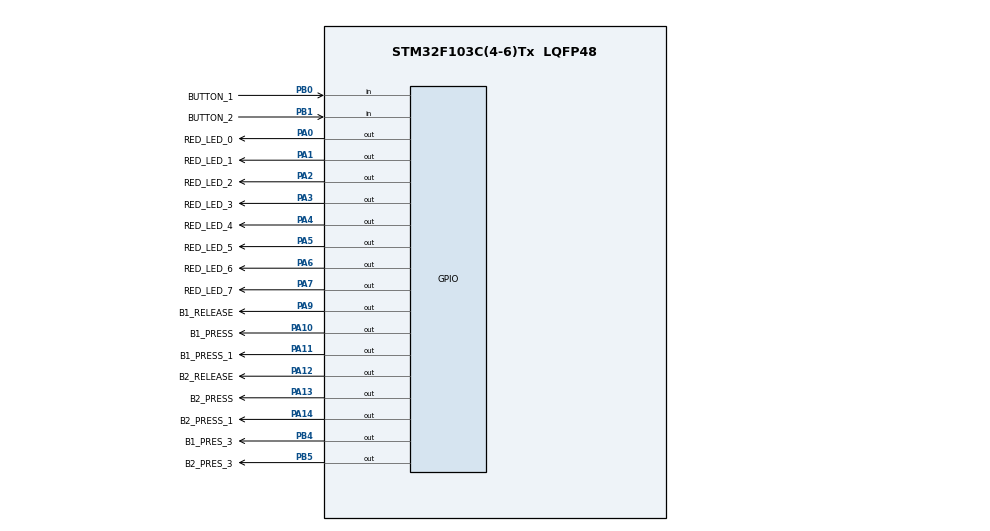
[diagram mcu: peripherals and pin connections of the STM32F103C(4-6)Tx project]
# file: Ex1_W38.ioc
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Mcu.Family=STM32F1
PD1-OSC_OUT.Mode=HSE-External-Oscillator
PA9.GPIO_Label=B1_RELEASE
PA14.GPIO_Label=B2_PRESS_1
PA11.GPIO_Label=B1_PRESS_1
PA6.GPIO_Label=RED_LED_6
PB0.GPIO_Label=BUTTON_1
PD0-OSC_IN.Signal=RCC_OSC_IN
VP_SYS_VS_ND.Mode=No_Debug
PA12.GPIO_Label=B2_RELEASE
ProjectManager.StackSize=0x400
PA0-WKUP.GPIO_Label=RED_LED_0
PA0-WKUP.Signal=GPIO_Output
PD1-OSC_OUT.Signal=RCC_OSC_OUT
PA13.Signal=GPIO_Output
PA12.Signal=GPIO_Output
ProjectManager.TargetToolchain=STM32CubeIDE
PA9.Signal=GPIO_Output
PA1.Signal=GPIO_Output
PD0-OSC_IN.Mode=HSE-External-Oscillator
PA5.Signal=GPIO_Output
board=custom
RCC.APB2Freq_Value=8000000
PB4.GPIO_Label=B1_PRES_3
VP_TIM2_VS_ClockSourceINT.Mode=Internal
PB1.GPIO_Label=BUTTON_2
NVIC.TIM2_IRQn=true\:0\:0\:false\:false\:true\:true\:true
PA1.GPIO_Label=RED_LED_1
PA10.GPIO_Label=B1_PRESS
TIM2.Period=9
Mcu.Name=STM32F103C(4-6)Tx
PA2.Signal=GPIO_Output
PA13.GPIO_Label=B2_PRESS
PA4.Signal=GPIO_Output
Mcu.Package=LQFP48
PB5.Signal=GPIO_Output
TIM2.Prescaler=7999
PA6.Signal=GPIO_Output
PB1.Signal=GPIO_Input
PA7.GPIO_Label=RED_LED_7
PA5.GPIO_Label=RED_LED_5
PA2.GPIO_Label=RED_LED_2
PA11.Signal=GPIO_Output
PA10.Signal=GPIO_Output
PA14.Signal=GPIO_Output
ProjectManager.HeapSize=0x200
NVIC.PriorityGroup=NVIC_PRIORITYGROUP_4
PB5.GPIO_Label=B2_PRES_3
RCC.APB1Freq_Value=8000000
PB0.Signal=GPIO_Input
PA4.GPIO_Label=RED_LED_4
PB4.Signal=GPIO_Output
PA3.GPIO_Label=RED_LED_3
PA3.Signal=GPIO_Output
PA7.Signal=GPIO_Output

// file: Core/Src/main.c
/* USER CODE BEGIN Header */
/**
  ******************************************************************************
  * @file           : main.c
  * @brief          : Main program body
  ******************************************************************************
  * @attention
  *
  * <h2><center>&copy; Copyright (c) 2021 STMicroelectronics.
  * All rights reserved.</center></h2>
  *
  * This software component is licensed by ST under BSD 3-Clause license,
  * the "License"; You may not use this file except in compliance with the
  * License. You may obtain a copy of the License at:
  *                        opensource.org/licenses/BSD-3-Clause
  *
  ******************************************************************************
  */
/* USER CODE END Header */
#include "main.h"
#include "input_processing.h"

#define time_auto_incre_I 50 // 0.5 s
#define time_auto_incre_II 10 //0.1 s

int count = 20;
int down=100; //1down = 10ms

int flag_auto_incre_I = 0;
int flag_auto_incre_II = 0;
int flag_auto_decre_I = 0;
int flag_auto_decre_II = 0;

enum ButtonState {BUTTONS_RELEASED, BUTTON1_PRESSED, BUTTON1_PRESSED_MORE_THAN_1_SECOND, BUTTON1_PRESSED_MORE_THAN_3_SECOND,
									BUTTON2_PRESSED, BUTTON2_PRESSED_MORE_THAN_1_SECOND, BUTTON2_PRESSED_MORE_THAN_3_SECOND};
enum ButtonState buttonState = BUTTONS_RELEASED ;
void ledofbutton(void)
{
	switch ( buttonState ){
		case BUTTONS_RELEASED:
			HAL_GPIO_WritePin(GPIOA, GPIO_PIN_9, 0);
			HAL_GPIO_WritePin(GPIOA, GPIO_PIN_10, 1);
			HAL_GPIO_WritePin(GPIOA, GPIO_PIN_11, 1);
			HAL_GPIO_WritePin(GPIOB, GPIO_PIN_4, 1);
			HAL_GPIO_WritePin(GPIOA, GPIO_PIN_12, 0);
			HAL_GPIO_WritePin(GPIOA, GPIO_PIN_13, 1);
			HAL_GPIO_WritePin(GPIOA, GPIO_PIN_14, 1);
			HAL_GPIO_WritePin(GPIOB, GPIO_PIN_5, 1);
			break;
		case BUTTON1_PRESSED:
			HAL_GPIO_WritePin(GPIOA, GPIO_PIN_9, 1);
			HAL_GPIO_WritePin(GPIOA, GPIO_PIN_10, 0);
			HAL_GPIO_WritePin(GPIOA, GPIO_PIN_11, 1);
			HAL_GPIO_WritePin(GPIOB, GPIO_PIN_4, 1);
			break;
		case BUTTON1_PRESSED_MORE_THAN_1_SECOND:
			HAL_GPIO_WritePin(GPIOA, GPIO_PIN_9, 1);
			HAL_GPIO_WritePin(GPIOA, GPIO_PIN_10, 1);
			HAL_GPIO_WritePin(GPIOA, GPIO_PIN_11, 0);
			HAL_GPIO_WritePin(GPIOB, GPIO_PIN_4, 1);
			break;
		case BUTTON1_PRESSED_MORE_THAN_3_SECOND:
			HAL_GPIO_WritePin(GPIOA, GPIO_PIN_9, 1);
			HAL_GPIO_WritePin(GPIOA, GPIO_PIN_10, 1);
			HAL_GPIO_WritePin(GPIOA, GPIO_PIN_11, 1);
			HAL_GPIO_WritePin(GPIOB, GPIO_PIN_4, 0);
			break;
		case BUTTON2_PRESSED:
			HAL_GPIO_WritePin(GPIOA, GPIO_PIN_12, 1);
			HAL_GPIO_WritePin(GPIOA, GPIO_PIN_13, 0);
			HAL_GPIO_WritePin(GPIOA, GPIO_PIN_14, 1);
			HAL_GPIO_WritePin(GPIOB, GPIO_PIN_5, 1);
			break;
		case BUTTON2_PRESSED_MORE_THAN_1_SECOND:
			HAL_GPIO_WritePin(GPIOA, GPIO_PIN_12, 1);
			HAL_GPIO_WritePin(GPIOA, GPIO_PIN_13, 1);
			HAL_GPIO_WritePin(GPIOA, GPIO_PIN_14, 0);
			HAL_GPIO_WritePin(GPIOB, GPIO_PIN_5, 1);
			break;
		case BUTTON2_PRESSED_MORE_THAN_3_SECOND:
			HAL_GPIO_WritePin(GPIOA, GPIO_PIN_12, 1);
			HAL_GPIO_WritePin(GPIOA, GPIO_PIN_13, 1);
			HAL_GPIO_WritePin(GPIOA, GPIO_PIN_14, 1);
			HAL_GPIO_WritePin(GPIOB, GPIO_PIN_5, 0);
			break;
		default:
			break;
	}
}
void fsm_for_input_processing(void){
	ledofbutton();
	switch ( buttonState ){
	case BUTTONS_RELEASED:
		if(get_button_value(0) == GPIO_PIN_RESET ) {
			buttonState = BUTTON1_PRESSED;
			count++;
		}
		else
		{
			if(get_button_value(1) == GPIO_PIN_RESET ) {
				buttonState = BUTTON2_PRESSED;
				count--;
			}
		}
		break;
	case BUTTON1_PRESSED:
		if(get_button_value(0) == GPIO_PIN_SET && get_button_value(1) == GPIO_PIN_SET ) { // release 2 button
			buttonState = BUTTONS_RELEASED ;
		} else {
			if(get_button_value(0) == GPIO_PIN_SET && get_button_value(1) == GPIO_PIN_RESET ) { // release button 0 but still press button 1
				buttonState = BUTTON2_PRESSED ;
			}
			else
			{
				if( get_flag_for_button_press_1s (0) == 1) {
					buttonState = BUTTON1_PRESSED_MORE_THAN_1_SECOND ;
				}
			}
		}
		break;
	case BUTTON1_PRESSED_MORE_THAN_1_SECOND :
		if(get_button_value(0) == GPIO_PIN_SET && get_button_value(1) == GPIO_PIN_SET) { // release 2 button
			buttonState = BUTTONS_RELEASED ;
			flag_auto_incre_I = 0;
		}
		else
		{
			if(get_button_value(0) == GPIO_PIN_SET && get_button_value(1) == GPIO_PIN_RESET ) { // release button 0 but still press button 1
				buttonState = BUTTON2_PRESSED ;
				count--;
				flag_auto_incre_I = 0;
			}
			else
			{
				flag_auto_incre_I = 1;
				if( get_flag_for_button_press_3s (0) == 1) {
					buttonState = BUTTON1_PRESSED_MORE_THAN_3_SECOND ;
					flag_auto_incre_I = 0;
				}
			}
		}
		break;
	case BUTTON1_PRESSED_MORE_THAN_3_SECOND :
		if(get_button_value(0) == GPIO_PIN_SET && get_button_value(1) == GPIO_PIN_SET ) { // release 2 button
			buttonState = BUTTONS_RELEASED ;
			flag_auto_incre_II = 0;
		}
		else
		{
			if(get_button_value(0) == GPIO_PIN_SET && get_button_value(1) == GPIO_PIN_RESET ) { // release button 0 but still press button 1
				buttonState = BUTTON2_PRESSED ;
				count--;
				flag_auto_incre_II = 0;
			}
			else
			{
				flag_auto_incre_II = 1;
			}
		}
		break;
	case BUTTON2_PRESSED:
		if(get_button_value(0) == GPIO_PIN_SET && get_button_value(1) == GPIO_PIN_SET ) { // release 2 button
			buttonState = BUTTONS_RELEASED ;
		} else {
			if(get_button_value(0) == GPIO_PIN_RESET && get_button_value(1) == GPIO_PIN_RESET ) { // press button 1 while pressing button 2
				buttonState = BUTTON1_PRESSED ;
				count++;
			}
			else
			{
				if( get_flag_for_button_press_1s (1) == 1) {
					buttonState = BUTTON2_PRESSED_MORE_THAN_1_SECOND ;
				}
			}
		}
		break;
	case BUTTON2_PRESSED_MORE_THAN_1_SECOND:
		if(get_button_value(0) == GPIO_PIN_SET && get_button_value(1) == GPIO_PIN_SET) { // release 2 button
			buttonState = BUTTONS_RELEASED ;
			flag_auto_decre_I = 0;
		}
		else
		{
			if(get_button_value(0) == GPIO_PIN_RESET && get_button_value(1) == GPIO_PIN_RESET ) { // press button 1 while pressing button 2
				buttonState = BUTTON1_PRESSED ;
				flag_auto_decre_I = 0;
				count++;
			}
			else
			{
				flag_auto_decre_I = 1;
				if( get_flag_for_button_press_3s (1) == 1) {
					buttonState = BUTTON2_PRESSED_MORE_THAN_3_SECOND ;
					flag_auto_decre_I = 0;
				}
			}
		}
		break;
	case BUTTON2_PRESSED_MORE_THAN_3_SECOND:
		if(get_button_value(0) == GPIO_PIN_SET && get_button_value(1) == GPIO_PIN_SET ) { // release 2 button
			buttonState = BUTTONS_RELEASED ;
			flag_auto_decre_II = 0;
		}
		else
		{
			if(get_button_value(0) == GPIO_PIN_RESET && get_button_value(1) == GPIO_PIN_RESET ) { // release button 0 but still press button 1
				buttonState = BUTTON1_PRESSED ;
				count++;
				flag_auto_decre_II = 0;
			}
			else
			{
				flag_auto_decre_II = 1;
			}
		}
		break;
	default:
			break;
	}
}

void display8leds(int value)
{
	if(value>=0)
	{
		int bin[8];
		for(int i=0; i<8;i++)
		{
			bin[i]=1-value%2;
			value/=2;
		}
		HAL_GPIO_WritePin(GPIOA, GPIO_PIN_0, bin[0]);
		HAL_GPIO_WritePin(GPIOA, GPIO_PIN_1, bin[1]);
		HAL_GPIO_WritePin(GPIOA, GPIO_PIN_2, bin[2]);
		HAL_GPIO_WritePin(GPIOA, GPIO_PIN_3, bin[3]);
		HAL_GPIO_WritePin(GPIOA, GPIO_PIN_4, bin[4]);
		HAL_GPIO_WritePin(GPIOA, GPIO_PIN_5, bin[5]);
		HAL_GPIO_WritePin(GPIOA, GPIO_PIN_6, bin[6]);
		HAL_GPIO_WritePin(GPIOA, GPIO_PIN_7, bin[7]);
	}
	else value = 0;
}

TIM_HandleTypeDef htim2;

void SystemClock_Config(void);
static void MX_GPIO_Init(void);
static void MX_TIM2_Init(void);

int main(void)
{

  /* MCU Configuration--------------------------------------------------------*/

  /* Reset of all peripherals, Initializes the Flash interface and the Systick. */
  HAL_Init();

  /* Configure the system clock */
  SystemClock_Config();

  /* Initialize all configured peripherals */
  MX_GPIO_Init();
  MX_TIM2_Init();
  /* USER CODE BEGIN 2 */
  HAL_TIM_Base_Start_IT(&htim2);
  /* USER CODE END 2 */

  /* Infinite loop */
  while (1)
  {

	  fsm_for_input_processing();
	  display8leds(count);

  }
}

void SystemClock_Config(void)
{
  RCC_OscInitTypeDef RCC_OscInitStruct = {0};
  RCC_ClkInitTypeDef RCC_ClkInitStruct = {0};

  /** Initializes the RCC Oscillators according to the specified parameters
  * in the RCC_OscInitTypeDef structure.
  */
  RCC_OscInitStruct.OscillatorType = RCC_OSCILLATORTYPE_HSI;
  RCC_OscInitStruct.HSIState = RCC_HSI_ON;
  RCC_OscInitStruct.HSICalibrationValue = RCC_HSICALIBRATION_DEFAULT;
  RCC_OscInitStruct.PLL.PLLState = RCC_PLL_NONE;
  if (HAL_RCC_OscConfig(&RCC_OscInitStruct) != HAL_OK)
  {
    Error_Handler();
  }
  /** Initializes the CPU, AHB and APB buses clocks
  */
  RCC_ClkInitStruct.ClockType = RCC_CLOCKTYPE_HCLK|RCC_CLOCKTYPE_SYSCLK
                              |RCC_CLOCKTYPE_PCLK1|RCC_CLOCKTYPE_PCLK2;
  RCC_ClkInitStruct.SYSCLKSource = RCC_SYSCLKSOURCE_HSI;
  RCC_ClkInitStruct.AHBCLKDivider = RCC_SYSCLK_DIV1;
  RCC_ClkInitStruct.APB1CLKDivider = RCC_HCLK_DIV1;
  RCC_ClkInitStruct.APB2CLKDivider = RCC_HCLK_DIV1;

  if (HAL_RCC_ClockConfig(&RCC_ClkInitStruct, FLASH_LATENCY_0) != HAL_OK)
  {
    Error_Handler();
  }
}

static void MX_TIM2_Init(void)
{

  TIM_ClockConfigTypeDef sClockSourceConfig = {0};
  TIM_MasterConfigTypeDef sMasterConfig = {0};

  htim2.Instance = TIM2;
  htim2.Init.Prescaler = 7999;
  htim2.Init.CounterMode = TIM_COUNTERMODE_UP;
  htim2.Init.Period = 9;
  htim2.Init.ClockDivision = TIM_CLOCKDIVISION_DIV1;
  htim2.Init.AutoReloadPreload = TIM_AUTORELOAD_PRELOAD_DISABLE;
  if (HAL_TIM_Base_Init(&htim2) != HAL_OK)
  {
    Error_Handler();
  }
  sClockSourceConfig.ClockSource = TIM_CLOCKSOURCE_INTERNAL;
  if (HAL_TIM_ConfigClockSource(&htim2, &sClockSourceConfig) != HAL_OK)
  {
    Error_Handler();
  }
  sMasterConfig.MasterOutputTrigger = TIM_TRGO_RESET;
  sMasterConfig.MasterSlaveMode = TIM_MASTERSLAVEMODE_DISABLE;
  if (HAL_TIMEx_MasterConfigSynchronization(&htim2, &sMasterConfig) != HAL_OK)
  {
    Error_Handler();
  }

}

static void MX_GPIO_Init(void)
{
  GPIO_InitTypeDef GPIO_InitStruct = {0};

  /* GPIO Ports Clock Enable */
  __HAL_RCC_GPIOD_CLK_ENABLE();
  __HAL_RCC_GPIOA_CLK_ENABLE();
  __HAL_RCC_GPIOB_CLK_ENABLE();

  /*Configure GPIO pin Output Level */
  HAL_GPIO_WritePin(GPIOA, RED_LED_0_Pin|RED_LED_1_Pin|RED_LED_2_Pin|RED_LED_3_Pin
                          |RED_LED_4_Pin|RED_LED_5_Pin|RED_LED_6_Pin|RED_LED_7_Pin
                          |B1_RELEASE_Pin|B1_PRESS_Pin|B1_PRESS_1_Pin|B2_RELEASE_Pin
                          |B2_PRESS_Pin|B2_PRESS_1_Pin, GPIO_PIN_RESET);

  /*Configure GPIO pin Output Level */
  HAL_GPIO_WritePin(GPIOB, B1_PRES_3_Pin|B2_PRES_3_Pin, GPIO_PIN_RESET);

  /*Configure GPIO pins : RED_LED_0_Pin RED_LED_1_Pin RED_LED_2_Pin RED_LED_3_Pin
                           RED_LED_4_Pin RED_LED_5_Pin RED_LED_6_Pin RED_LED_7_Pin
                           B1_RELEASE_Pin B1_PRESS_Pin B1_PRESS_1_Pin B2_RELEASE_Pin
                           B2_PRESS_Pin B2_PRESS_1_Pin */
  GPIO_InitStruct.Pin = RED_LED_0_Pin|RED_LED_1_Pin|RED_LED_2_Pin|RED_LED_3_Pin
                          |RED_LED_4_Pin|RED_LED_5_Pin|RED_LED_6_Pin|RED_LED_7_Pin
                          |B1_RELEASE_Pin|B1_PRESS_Pin|B1_PRESS_1_Pin|B2_RELEASE_Pin
                          |B2_PRESS_Pin|B2_PRESS_1_Pin;
  GPIO_InitStruct.Mode = GPIO_MODE_OUTPUT_PP;
  GPIO_InitStruct.Pull = GPIO_NOPULL;
  GPIO_InitStruct.Speed = GPIO_SPEED_FREQ_LOW;
  HAL_GPIO_Init(GPIOA, &GPIO_InitStruct);

  /*Configure GPIO pins : BUTTON_1_Pin BUTTON_2_Pin */
  GPIO_InitStruct.Pin = BUTTON_1_Pin|BUTTON_2_Pin;
  GPIO_InitStruct.Mode = GPIO_MODE_INPUT;
  GPIO_InitStruct.Pull = GPIO_NOPULL;
  HAL_GPIO_Init(GPIOB, &GPIO_InitStruct);

  /*Configure GPIO pins : B1_PRES_3_Pin B2_PRES_3_Pin */
  GPIO_InitStruct.Pin = B1_PRES_3_Pin|B2_PRES_3_Pin;
  GPIO_InitStruct.Mode = GPIO_MODE_OUTPUT_PP;
  GPIO_InitStruct.Pull = GPIO_NOPULL;
  GPIO_InitStruct.Speed = GPIO_SPEED_FREQ_LOW;
  HAL_GPIO_Init(GPIOB, &GPIO_InitStruct);

}

/* USER CODE BEGIN 4 */
void HAL_TIM_PeriodElapsedCallback ( TIM_HandleTypeDef * htim )
{
	//do chu ki la 10ms nen ham nay xu li gi sau 10ms
	down--;
	if(down<=0)down=100;
	button_reading();
	if(flag_auto_incre_I==1 && down%time_auto_incre_I == 0) count++;
	if(flag_auto_incre_II==1 && down%time_auto_incre_II == 0) count++;
	if(flag_auto_decre_I==1 && down%time_auto_incre_I == 0) count--;
	if(flag_auto_decre_II==1 && down%time_auto_incre_II == 0) count--;
}
/* USER CODE END 4 */

void Error_Handler(void)
{
  __disable_irq();
  while (1)
  {
  }
}

/************************ (C) COPYRIGHT STMicroelectronics *****END OF FILE****/
